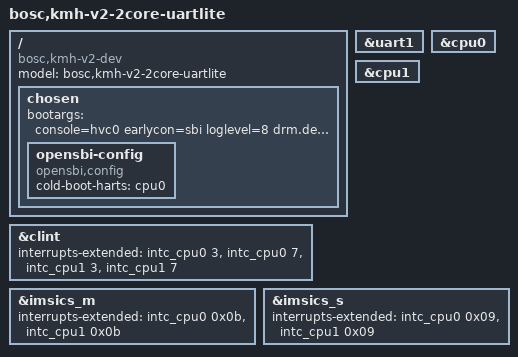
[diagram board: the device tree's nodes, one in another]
// SPDX-License-Identifier: (GPL-2.0 OR MIT)
/* Copyright (c) 2025 BOSC */

/dts-v1/;
#include "kmh-v2.dtsi"

/ {
	#address-cells = <2>;
	#size-cells = <2>;
	compatible = "bosc,kmh-v2-dev";
	model = "bosc,kmh-v2-2core-uartlite";

	chosen {
		bootargs = "console=hvc0 earlycon=sbi loglevel=8 drm.debug=0x2";
		opensbi-config {
		    compatible = "opensbi,config";
		    cold-boot-harts = <&cpu0>;
		};
	};
};

&uart1 {
	status = "okay";
};

&cpu0 {
	status = "okay";
};

&cpu1 {
	status = "okay";
};

&clint {
	interrupts-extended =
		<&intc_cpu0 3>, <&intc_cpu0 7>,
        <&intc_cpu1 3>, <&intc_cpu1 7>;
};

&imsics_m {
	interrupts-extended =
		<&intc_cpu0 0x0b>,
        <&intc_cpu1 0x0b>;
};

&imsics_s {
	interrupts-extended =
		<&intc_cpu0 0x09>,
        <&intc_cpu1 0x09>;
};
